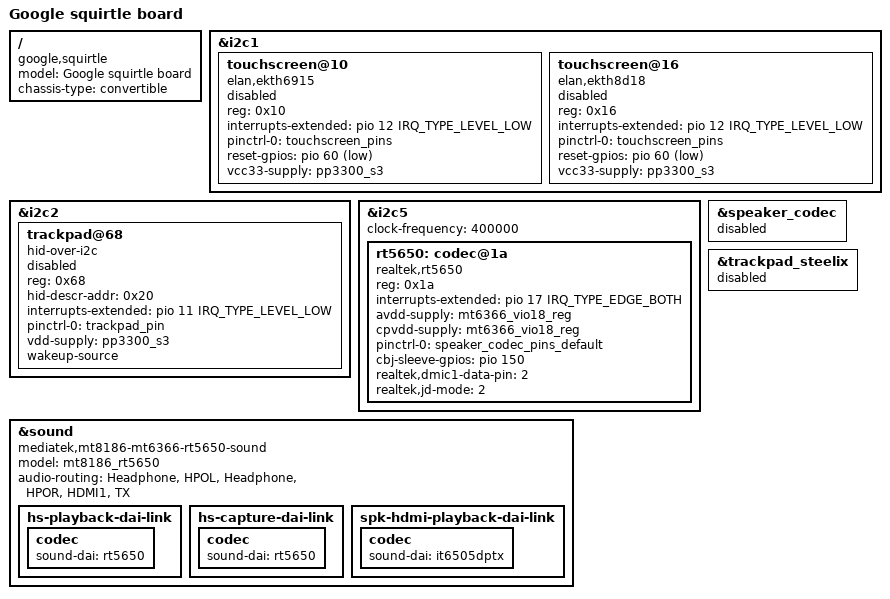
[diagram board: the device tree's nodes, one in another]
// SPDX-License-Identifier: (GPL-2.0 OR MIT)
/*
 * Copyright 2024 Google LLC
 */

/dts-v1/;
#include "mt8186-corsola-voltorb.dtsi"

/ {
	model = "Google squirtle board";
	compatible = "google,squirtle", "mediatek,mt8186";
	chassis-type = "convertible";
};

&i2c1 {
	touchscreen@10 {
		compatible = "elan,ekth6915";
		reg = <0x10>;
		interrupts-extended = <&pio 12 IRQ_TYPE_LEVEL_LOW>;
		pinctrl-names = "default";
		pinctrl-0 = <&touchscreen_pins>;
		reset-gpios = <&pio 60 GPIO_ACTIVE_LOW>;
		vcc33-supply = <&pp3300_s3>;
		status = "fail-needs-probe";
	};

	touchscreen@16 {
		compatible = "elan,ekth8d18", "elan,ekth6a12nay";
		reg = <0x16>;
		interrupts-extended = <&pio 12 IRQ_TYPE_LEVEL_LOW>;
		pinctrl-names = "default";
		pinctrl-0 = <&touchscreen_pins>;
		reset-gpios = <&pio 60 GPIO_ACTIVE_LOW>;
		vcc33-supply = <&pp3300_s3>;
		status = "fail-needs-probe";
	};
};

&i2c2 {
	trackpad@68 {
		compatible = "hid-over-i2c";
		reg = <0x68>;
		hid-descr-addr = <0x20>;
		interrupts-extended = <&pio 11 IRQ_TYPE_LEVEL_LOW>;
		pinctrl-names = "default";
		pinctrl-0 = <&trackpad_pin>;
		vdd-supply = <&pp3300_s3>;
		wakeup-source;
		status = "fail-needs-probe";
	};
};

&i2c5 {
	clock-frequency = <400000>;

	/delete-node/ codec@1a;

	rt5650: codec@1a {
		compatible = "realtek,rt5650";
		reg = <0x1a>;
		interrupts-extended = <&pio 17 IRQ_TYPE_EDGE_BOTH>;
		avdd-supply = <&mt6366_vio18_reg>;
		cpvdd-supply = <&mt6366_vio18_reg>;
		pinctrl-names = "default";
		pinctrl-0 = <&speaker_codec_pins_default>;
		cbj-sleeve-gpios = <&pio 150 GPIO_ACTIVE_HIGH>;
		#sound-dai-cells = <0>;
		realtek,dmic1-data-pin = <2>;
		realtek,jd-mode = <2>;
	};
};

&sound {
	compatible = "mediatek,mt8186-mt6366-rt5650-sound";
	model = "mt8186_rt5650";

	audio-routing =
		"Headphone", "HPOL",
		"Headphone", "HPOR",
		"HDMI1", "TX";

	hs-playback-dai-link {
		codec {
			sound-dai = <&rt5650>;
		};
	};

	hs-capture-dai-link {
		codec {
			sound-dai = <&rt5650>;
		};
	};

	spk-hdmi-playback-dai-link {
		codec {
			sound-dai = <&it6505dptx>;
		};
	};
};

&speaker_codec {
	status = "disabled";
};

&trackpad_steelix {
	status = "disabled";
};
